# STM32F0x2 register map
File version: 1.3
CPU: CM0 r0p0, little endian, no MPU, no FPU, 2 interrupt priority bits
Registers are 32-bit, read-write, reset 0x0 unless marked. A register's access mark holds for its fields unless they carry their own. Offsets are from the block's base; [hi:lo] are bit positions; {n}, {i} and the like mark numbered series.

## ADC — Analog-to-digital converter
Base 0x40012400
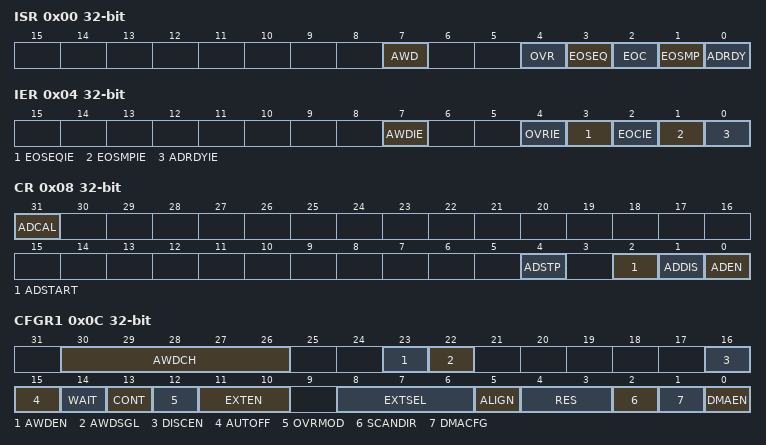
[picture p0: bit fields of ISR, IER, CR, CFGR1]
0x00 ISR — interrupt and status register
  [7] AWD write-1-clears — Analog watchdog flag
    on read: 0=NoEvent (No analog watchdog event occurred); 1=Event (Analog watchdog event occurred) | on write: 1=Clear the analog watchdog event flag
  [4] OVR write-1-clears — ADC overrun
    on read: 0=No overrun occurred; 1=Overrun occurred | on write: 1=Clear the overrun flag
  [3] EOSEQ write-1-clears — End of sequence flag
    on read: 0=NotComplete (Conversion sequence is not complete); 1=Complete (Conversion sequence complete) | on write: 1=Clear the conversion sequence flag
  [2] EOC write-1-clears — End of conversion flag
    on read: 0=NotComplete (Channel conversion is not complete); 1=Complete (Channel conversion complete) | on write: 1=Clear the channel conversion flag
  [1] EOSMP write-1-clears — End of sampling flag
    on read: 0=NotAtEnd (Not at the end of the samplings phase); 1=AtEnd (End of sampling phase reached) | on write: 1=Clear the sampling phase flag
  [0] ADRDY write-1-clears — ADC ready
    on read: 0=NotReady (ADC not yet ready to start conversion); 1=Ready (ADC ready to start conversion) | on write: 1=Clear the ADC ready flag
0x04 IER — interrupt enable register
  [7] AWDIE — Analog watchdog interrupt enable
    0=Disabled (Analog watchdog interrupt disabled); 1=Enabled (Analog watchdog interrupt enabled)
  [4] OVRIE — Overrun interrupt enable
    0=Disabled (Overrun interrupt disabled); 1=Enabled (Overrun interrupt enabled)
  [3] EOSEQIE — End of conversion sequence interrupt enable
    0=Disabled (End of conversion sequence interrupt disabled); 1=Enabled (End of conversion sequence interrupt enabled)
  [2] EOCIE — End of conversion interrupt enable
    0=Disabled (End of conversion interrupt disabled); 1=Enabled (End of conversion interrupt enabled)
  [1] EOSMPIE — End of sampling flag interrupt enable
    0=Disabled (End of sampling interrupt disabled); 1=Enabled (End of sampling interrupt enabled)
  [0] ADRDYIE — ADC ready interrupt enable
    0=Disabled (ADC ready interrupt disabled); 1=Enabled (ADC ready interrupt enabled)
0x08 CR — control register
  [31] ADCAL write-1-sets — ADC calibration
    on read: 0=NotCalibrating (ADC calibration either not yet performed or completed); 1=Calibrating (ADC calibration in progress) | on write: 1=StartCalibration (Start the ADC calibration sequence)
  [4] ADSTP write-1-sets — ADC stop conversion command
    on read: 0=NotStopping (No stop command active); 1=Stopping (ADC stopping conversion) | on write: 1=StopConversion (Stop the active conversion)
  [2] ADSTART write-1-sets — ADC start conversion command
    on read: 0=NotActive (No conversion ongoing); 1=Active (ADC operating and may be converting) | on write: 1=StartConversion (Start the ADC conversion (may be delayed for hardware triggers))
  [1] ADDIS write-1-sets — ADC disable command
    on read: 0=NotDisabling (No disable command active); 1=Disabling (ADC disabling) | on write: 1=Disable the ADC
  [0] ADEN write-1-sets — ADC enable command
    on read: 0=Disabled (ADC disabled); 1=Enabled (ADC enabled) | on write: 1=Enabled (Enable the ADC)
0x0C CFGR1 — configuration register 1
  [30:26] AWDCH range 0..18 — Analog watchdog channel selection
  [23] AWDEN — Analog watchdog enable
    0=Disabled (Analog watchdog disabled on regular channels); 1=Enabled (Analog watchdog enabled on regular channels)
  [22] AWDSGL — Enable the watchdog on a single channel or on all channels
    0=AllChannels (Analog watchdog enabled on all channels); 1=SingleChannel (Analog watchdog enabled on a single channel)
  [16] DISCEN — Discontinuous mode
    0=Disabled (Discontinuous mode on regular channels disabled); 1=Enabled (Discontinuous mode on regular channels enabled)
  [15] AUTOFF — Auto-off mode
    0=Disabled (Auto-off mode disabled); 1=Enabled (Auto-off mode enabled)
  [14] WAIT — Wait conversion mode
    0=Disabled (Wait conversion mode off); 1=Enabled (Wait conversion mode on)
  [13] CONT — Single / continuous conversion mode
    0=Single conversion mode; 1=Continuous conversion mode
  [12] OVRMOD — Overrun management mode
    0=Preserved (ADC_DR register is preserved with the old data when an overrun is detected); 1=Overwritten (ADC_DR register is overwritten with the last conversion result when an overrun is detected)
  [11:10] EXTEN — External trigger enable and polarity selection
    0=Disabled (Trigger detection disabled); 1=RisingEdge (Trigger detection on the rising edge); 2=FallingEdge (Trigger detection on the falling edge); 3=BothEdges (Trigger detection on both the rising and falling edges)
  [8:6] EXTSEL — External trigger selection
    0=TIM1_TRGO (Timer 1 TRGO Event); 1=TIM1_CC4 (Timer 1 CC4 event); 2=TIM2_TRGO (Timer 2 TRGO event); 3=TIM3_TRGO (Timer 3 TRGO event); 4=TIM15_TRGO (Timer 15 TRGO event)
  [5] ALIGN — Data alignment
    0=Right alignment; 1=Left alignment
  [4:3] RES — Data resolution
    0=TwelveBit (12-bit (14 ADCCLK cycles)); 1=TenBit (10-bit (13 ADCCLK cycles)); 2=EightBit (8-bit (11 ADCCLK cycles)); 3=SixBit (6-bit (9 ADCCLK cycles))
  [2] SCANDIR — Scan sequence direction
    0=Upward scan (from CHSEL0 to CHSEL18); 1=Backward scan (from CHSEL18 to CHSEL0)
  [1] DMACFG — Direct memery access configuration
    0=OneShot (DMA one shot mode); 1=Circular (DMA circular mode)
  [0] DMAEN — Direct memory access enable
    0=Disabled (DMA mode disabled); 1=Enabled (DMA mode enabled)
0x10 CFGR2 reset 0x8000 — configuration register 2
  [31:30] CKMODE — ADC clock mode
    0=ADCCLK (Asynchronous clock mode); 1=PCLK_Div2 (Synchronous clock mode (PCLK/2)); 2=PCLK_Div4 (Sychronous clock mode (PCLK/4))
0x14 SMPR — sampling time register
  [2:0] SMP — Sampling time selection
    0=Cycles1_5 (1.5 cycles); 1=Cycles7_5 (7.5 cycles); 2=Cycles13_5 (13.5 cycles); 3=Cycles28_5 (28.5 cycles); 4=Cycles41_5 (41.5 cycles); 5=Cycles55_5 (55.5 cycles); 6=Cycles71_5 (71.5 cycles); 7=Cycles239_5 (239.5 cycles)
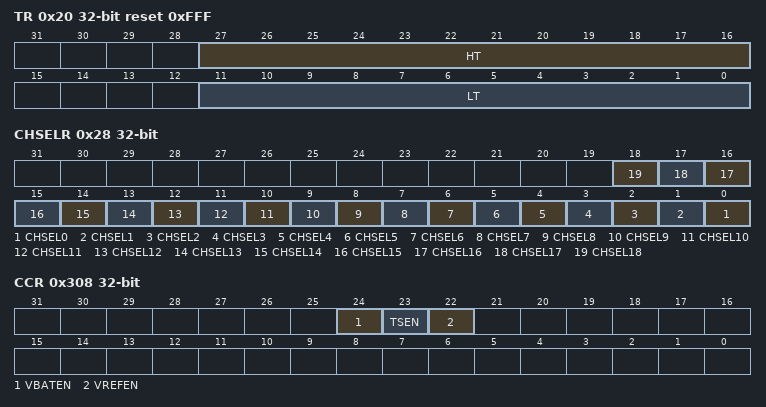
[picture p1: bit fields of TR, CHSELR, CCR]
0x20 TR reset 0xFFF — watchdog threshold register
  [27:16] HT — Analog watchdog higher threshold
  [11:0] LT — Analog watchdog lower threshold
0x28 CHSELR — channel selection register
  [n] CHSEL{n} (n=0..18) — Channel-x selection
    0=NotSelected (Input Channel is not selected for conversion); 1=Selected (Input Channel is selected for conversion)
0x40 DR ro — data register
  [15:0] DATA — Converted data
0x308 CCR — common configuration register
  [24] VBATEN — VBAT enable
    0=Disabled (V_BAT channel disabled); 1=Enabled (V_BAT channel enabled)
  [23] TSEN — Temperature sensor enable
    0=Disabled (Temperature sensor disabled); 1=Enabled (Temperature sensor enabled)
  [22] VREFEN — Temperature sensor and VREFINT enable
    0=Disabled (V_REFINT channel disabled); 1=Enabled (V_REFINT channel enabled)
